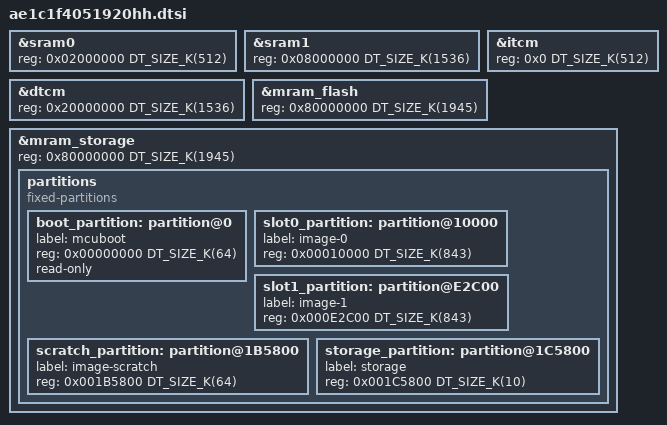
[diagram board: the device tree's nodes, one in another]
/* Copyright (c) 2025 Alif Semiconductor
 *
 * SPDX-License-Identifier: Apache-2.0
 */

#include "alif/ensemble/common/e1c.dtsi"

&sram0 {
	reg = <0x02000000 DT_SIZE_K(512)>;
};

&sram1 {
	reg = <0x08000000 DT_SIZE_K(1536)>;
};

&itcm {
	reg = <0x0 DT_SIZE_K(512)>;
};

&dtcm {
	reg = <0x20000000 DT_SIZE_K(1536)>;
};

&mram_flash {
	/* Usable MRAM size for applications is 1945 KB */
	reg = <0x80000000 DT_SIZE_K(1945)>;
};

&mram_storage {
	reg = <0x80000000 DT_SIZE_K(1945)>;
	partitions {
		compatible = "fixed-partitions";
		#address-cells = <1>;
		#size-cells = <1>;

		boot_partition: partition@0 {
			label = "mcuboot";
			reg = <0x00000000 DT_SIZE_K(64)>;
			read-only;
		};

		slot0_partition: partition@10000 {
			label = "image-0";
			reg = <0x00010000 DT_SIZE_K(843)>;
		};

		slot1_partition: partition@E2C00 {
			label = "image-1";
			reg = <0x000E2C00 DT_SIZE_K(843)>;
		};

		scratch_partition: partition@1B5800 {
			label = "image-scratch";
			reg = <0x001B5800 DT_SIZE_K(64)>;
		};

		storage_partition: partition@1C5800 {
			label = "storage";
			reg = <0x001C5800 DT_SIZE_K(10)>;
		};
	};
};
